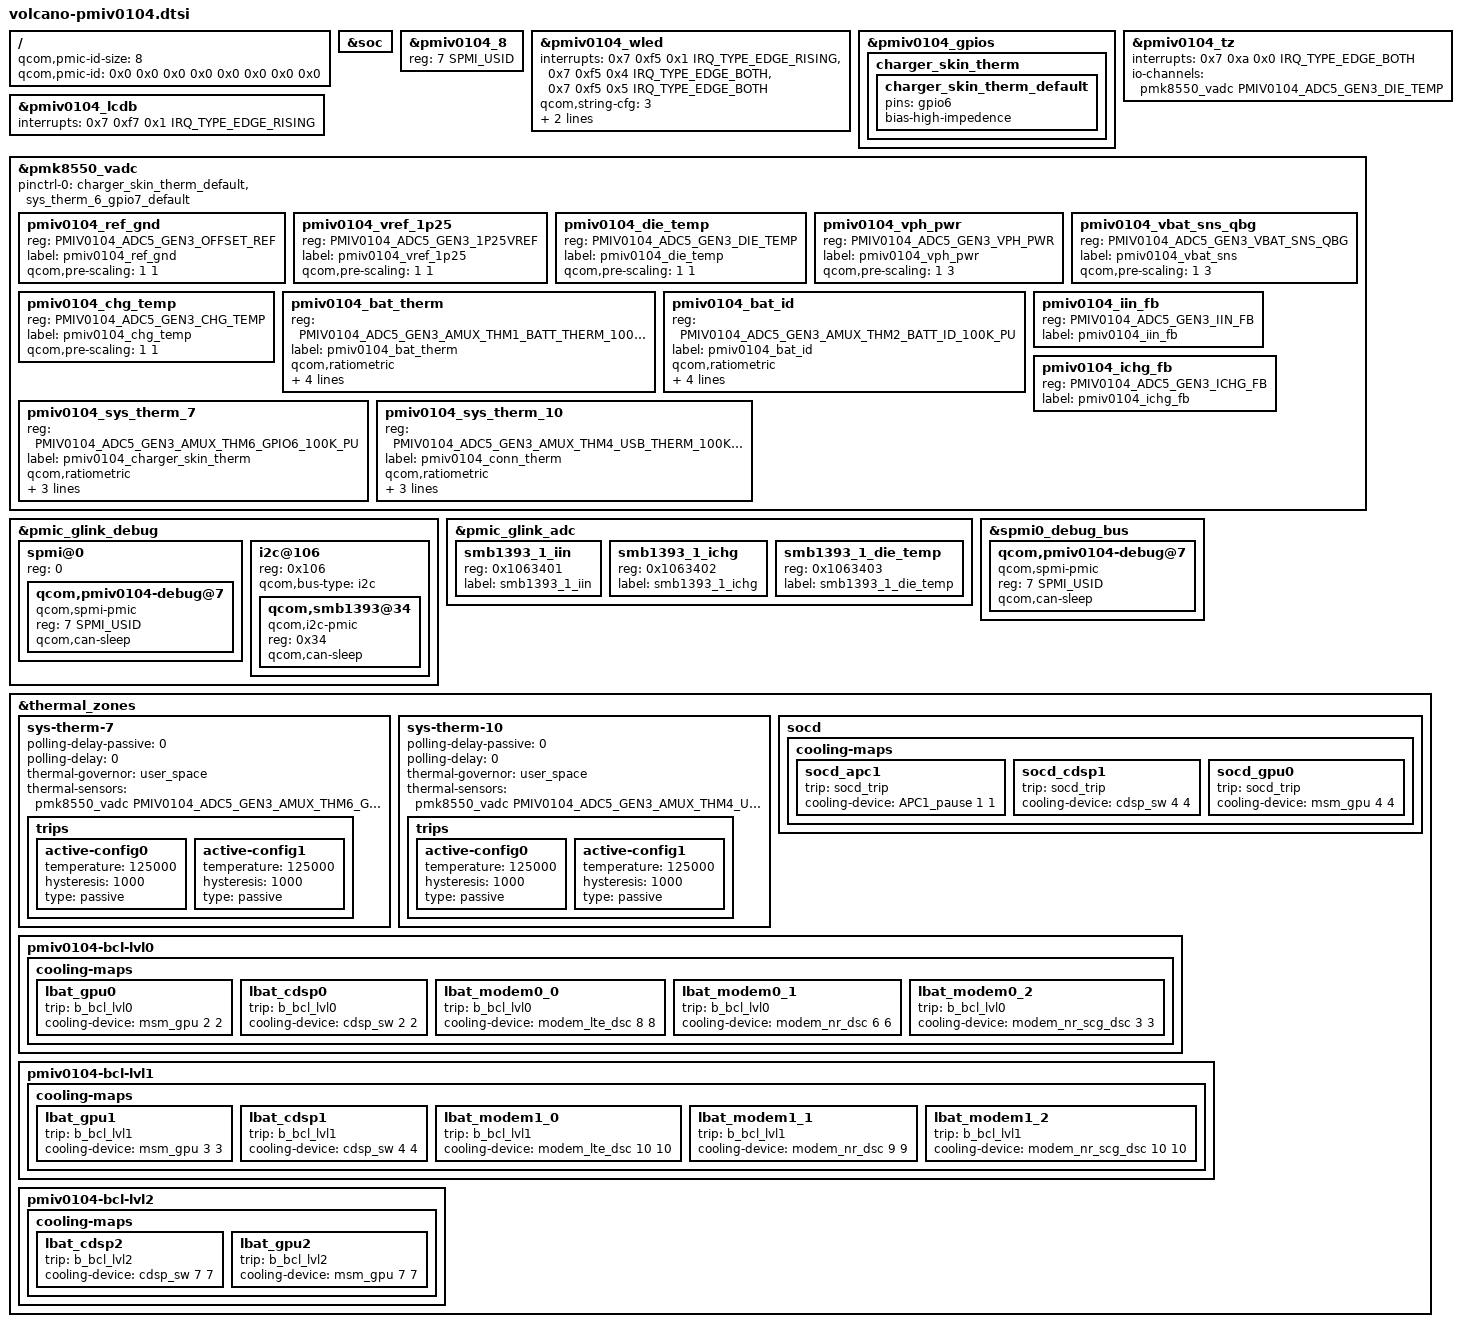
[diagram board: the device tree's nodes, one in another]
#include <dt-bindings/iio/qcom,spmi-vadc.h>
#include <dt-bindings/iio/qcom,spmi-adc5-gen3-pmiv0104.h>
#include "pmiv0104.dtsi"

/ {
	qcom,pmic-id-size = <8>;
	qcom,pmic-id = <0x0 0x0 0x0 0x0 0x0 0x0 0x0 0x0>;
};

&soc {
};

&pmiv0104_8 {
	reg = <7 SPMI_USID>;
};

&pmiv0104_wled {
	interrupts = <0x7 0xf5 0x1 IRQ_TYPE_EDGE_RISING>,
			<0x7 0xf5 0x4 IRQ_TYPE_EDGE_BOTH>,
			<0x7 0xf5 0x5 IRQ_TYPE_EDGE_BOTH>;
	qcom,string-cfg = <3>;
	qcom,leds-per-string = <8>;
	qcom,fs-current-limit = <22500>;
};

&pmiv0104_gpios {
	charger_skin_therm {
		charger_skin_therm_default: charger_skin_therm_default {
			pins = "gpio6";
			bias-high-impedence;
		};
	};
};

&pmiv0104_tz {
	interrupts = <0x7 0xa 0x0 IRQ_TYPE_EDGE_BOTH>;
};

&pmiv0104_lcdb {
	interrupts = <0x7 0xf7 0x1 IRQ_TYPE_EDGE_RISING>;
};

&pmiv0104_tz {
	interrupts = <0x7 0xa 0x0 IRQ_TYPE_EDGE_BOTH>;
	io-channels = <&pmk8550_vadc PMIV0104_ADC5_GEN3_DIE_TEMP>;
	io-channel-names = "thermal";

};

&pmk8550_vadc {
	pinctrl-names = "default";
	pinctrl-0 = <&charger_skin_therm_default &sys_therm_6_gpio7_default>;

	pmiv0104_ref_gnd {
		reg = <PMIV0104_ADC5_GEN3_OFFSET_REF>;
		label = "pmiv0104_ref_gnd";
		qcom,pre-scaling = <1 1>;
	};

	pmiv0104_vref_1p25 {
		reg = <PMIV0104_ADC5_GEN3_1P25VREF>;
		label = "pmiv0104_vref_1p25";
		qcom,pre-scaling = <1 1>;
	};

	pmiv0104_die_temp {
		reg = <PMIV0104_ADC5_GEN3_DIE_TEMP>;
		label = "pmiv0104_die_temp";
		qcom,pre-scaling = <1 1>;
	};

	pmiv0104_vph_pwr {
		reg = <PMIV0104_ADC5_GEN3_VPH_PWR>;
		label = "pmiv0104_vph_pwr";
		qcom,pre-scaling = <1 3>;
	};

	pmiv0104_vbat_sns_qbg {
		reg = <PMIV0104_ADC5_GEN3_VBAT_SNS_QBG>;
		label = "pmiv0104_vbat_sns";
		qcom,pre-scaling = <1 3>;
	};

	pmiv0104_chg_temp {
		reg = <PMIV0104_ADC5_GEN3_CHG_TEMP>;
		label = "pmiv0104_chg_temp";
		qcom,pre-scaling = <1 1>;
	};

	pmiv0104_bat_therm {
		reg = <PMIV0104_ADC5_GEN3_AMUX_THM1_BATT_THERM_100K_PU>;
		label = "pmiv0104_bat_therm";
		qcom,ratiometric;
		qcom,hw-settle-time = <200>;
		qcom,pre-scaling = <1 1>;
		qcom,scale-fn-type = <ADC_SCALE_HW_CALIB_PM5_GEN3_BATT_THERM_100K>;
	};

	pmiv0104_bat_id {
		reg = <PMIV0104_ADC5_GEN3_AMUX_THM2_BATT_ID_100K_PU>;
		label = "pmiv0104_bat_id";
		qcom,ratiometric;
		qcom,hw-settle-time = <200>;
		qcom,pre-scaling = <1 1>;
		qcom,scale-fn-type = <ADC_SCALE_HW_CALIB_PM5_GEN3_BATT_ID_100K>;
	};

	pmiv0104_iin_fb {
		reg = <PMIV0104_ADC5_GEN3_IIN_FB>;
		label = "pmiv0104_iin_fb";
	};

	pmiv0104_ichg_fb {
		reg = <PMIV0104_ADC5_GEN3_ICHG_FB>;
		label = "pmiv0104_ichg_fb";
	};

	pmiv0104_sys_therm_7 {
		reg = <PMIV0104_ADC5_GEN3_AMUX_THM6_GPIO6_100K_PU>;
		label = "pmiv0104_charger_skin_therm";
		qcom,ratiometric;
		qcom,hw-settle-time = <200>;
		qcom,pre-scaling = <1 1>;
		qcom,adc-tm-type = <1>;
	};

	pmiv0104_sys_therm_10 {
		reg = <PMIV0104_ADC5_GEN3_AMUX_THM4_USB_THERM_100K_PU>;
		label = "pmiv0104_conn_therm";
		qcom,ratiometric;
		qcom,hw-settle-time = <200>;
		qcom,pre-scaling = <1 1>;
		qcom,adc-tm-type = <1>;
	};
};

&pmic_glink_debug {
	spmi@0 {
		reg = <0>;
		#address-cells = <2>;
		#size-cells = <0>;
		qcom,pmiv0104-debug@7 {
			compatible = "qcom,spmi-pmic";
			reg = <7 SPMI_USID>;
			qcom,can-sleep;
		};
	};

	i2c@106 {
		reg = <0x106>;  /* I2C instance 6 in ADSP for SE7 */
		#address-cells = <1>;
		#size-cells = <0>;
		qcom,bus-type = "i2c";

		qcom,smb1393@34 {
			compatible = "qcom,i2c-pmic";
			reg = <0x34>;
			qcom,can-sleep;
		};
	};
};

&pmic_glink_adc {
	status = "ok";

	smb1393_1_iin {
		reg = <0x1063401>;
		label = "smb1393_1_iin";
	};

	smb1393_1_ichg {
		reg = <0x1063402>;
		label = "smb1393_1_ichg";
	};

	smb1393_1_die_temp {
		reg = <0x1063403>;
		label = "smb1393_1_die_temp";
	};
};

&spmi0_debug_bus {
	qcom,pmiv0104-debug@7 {
		compatible = "qcom,spmi-pmic";
		reg = <7 SPMI_USID>;
		#address-cells = <2>;
		#size-cells = <0>;
		qcom,can-sleep;
	};
};

&thermal_zones {
	sys-therm-7 {
		polling-delay-passive = <0>;
		polling-delay = <0>;
		thermal-governor = "user_space";
		thermal-sensors = <&pmk8550_vadc PMIV0104_ADC5_GEN3_AMUX_THM6_GPIO6_100K_PU>;
		trips {
			active-config0 {
				temperature = <125000>;
				hysteresis = <1000>;
				type = "passive";
			};

			active-config1 {
				temperature = <125000>;
				hysteresis = <1000>;
				type = "passive";
			};
		};
	};

	sys-therm-10 {
		polling-delay-passive = <0>;
		polling-delay = <0>;
		thermal-governor = "user_space";
		thermal-sensors = <&pmk8550_vadc PMIV0104_ADC5_GEN3_AMUX_THM4_USB_THERM_100K_PU>;
		trips {
			active-config0 {
				temperature = <125000>;
				hysteresis = <1000>;
				type = "passive";
			};

			active-config1 {
				temperature = <125000>;
				hysteresis = <1000>;
				type = "passive";
			};
		};
	};
};

&thermal_zones {
	socd {
		cooling-maps {
			socd_apc1 {
				trip = <&socd_trip>;
				cooling-device = <&APC1_pause 1 1>;
			};

			socd_cdsp1 {
				trip = <&socd_trip>;
				cooling-device = <&cdsp_sw 4 4>;
			};

			socd_gpu0 {
				trip = <&socd_trip>;
				cooling-device = <&msm_gpu 4 4>;
			};
		};
	};

	pmiv0104-bcl-lvl0 {
		cooling-maps {
			lbat_gpu0 {
				trip = <&b_bcl_lvl0>;
				cooling-device = <&msm_gpu 2 2>;
			};

			lbat_cdsp0 {
				trip = <&b_bcl_lvl0>;
				cooling-device = <&cdsp_sw 2 2>;
			};

			lbat_modem0_0 {
				trip = <&b_bcl_lvl0>;
				cooling-device = <&modem_lte_dsc 8 8>;
			};

			lbat_modem0_1 {
				trip = <&b_bcl_lvl0>;
				cooling-device = <&modem_nr_dsc 6 6>;
			};

			lbat_modem0_2 {
				trip = <&b_bcl_lvl0>;
				cooling-device = <&modem_nr_scg_dsc 3 3>;
			};
		};
	};

	pmiv0104-bcl-lvl1 {
		cooling-maps {
			lbat_gpu1 {
				trip = <&b_bcl_lvl1>;
				cooling-device = <&msm_gpu 3 3>;
			};

			lbat_cdsp1 {
				trip = <&b_bcl_lvl1>;
				cooling-device = <&cdsp_sw 4 4>;
			};

			lbat_modem1_0 {
				trip = <&b_bcl_lvl1>;
				cooling-device = <&modem_lte_dsc 10 10>;
			};

			lbat_modem1_1 {
				trip = <&b_bcl_lvl1>;
				cooling-device = <&modem_nr_dsc 9 9>;
			};

			lbat_modem1_2 {
				trip = <&b_bcl_lvl1>;
				cooling-device = <&modem_nr_scg_dsc 10 10>;
			};
		};
	};

	pmiv0104-bcl-lvl2 {
		cooling-maps {
			lbat_cdsp2 {
				trip = <&b_bcl_lvl2>;
				cooling-device = <&cdsp_sw 7 7>;
			};

			lbat_gpu2 {
				trip = <&b_bcl_lvl2>;
				cooling-device = <&msm_gpu 7 7>;
			};
		};
	};
};
